# CONTROLSS_PWMXBAR_CONTROLSS_502D1000h register map
Vendor: Texas Instruments
Peripheral module from a debugger description file (folder AM263P).
Registers are 32-bit, read-write, reset 0x0 unless marked. A register's access mark holds for its fields unless they carry their own. Offsets are as the file gives them; lines under a group give offsets from that group; [hi:lo] are bit positions; {n}, {i} and the like mark numbered series; 'fields as' and 'values as' point back to an identical list; <NAME> marks a mode.

## CONTROLSS
0x10 CONTROLSS_PWMXBAR_STATUS ro — Output Signal Status.
  [29:0] PWMXBAR_STATUS_STS — Output Signal Status
0x14 CONTROLSS_PWMXBAR_FLAGINVERT — Output Signal Invert Before Latch.
  [29:0] PWMXBAR_FLAGINVERT_INVERT — Output Signal Invert Before Latch
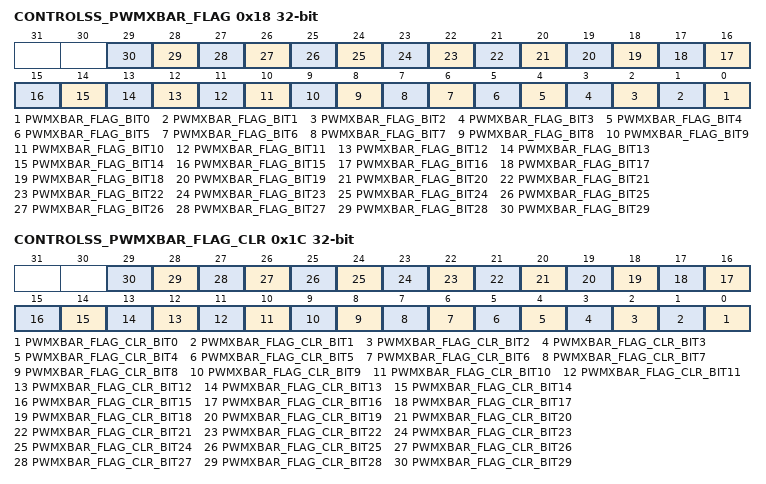
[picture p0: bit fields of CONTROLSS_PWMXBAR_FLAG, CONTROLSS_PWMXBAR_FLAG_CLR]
0x18 CONTROLSS_PWMXBAR_FLAG — Output Signal Latched Flag.
  [n] PWMXBAR_FLAG_BIT{n} (n=0..29) — Output Signal Latched Flag
0x1C CONTROLSS_PWMXBAR_FLAG_CLR — Output Signal Latched Flag Clear.
  [n] PWMXBAR_FLAG_CLR_BIT{n} (n=0..29) — Output Signal Latched Flag Clear
{0x100+0x40*i} CONTROLSS_PWMXBAR{i}_G0 (i=0..29) — PWM XBAR {i} Input Select.
  [19:0] PWMXBAR{i}_G0_SEL — PWM XBAR{i} G0 Input SelectBit0:CMP12SS0.CTRIPLBit1:CMP12SS0.CTRIPHBit2:CMP12SS1.CTRIPLBit3:CMP12SS1.CTRIPHBit4:CMP12SS2.CTRIPLBit5:CMP12SS2.CTRIPHBit6:CMP12SS3.CTRIPLBit7:CMP12SS3.CTRIPHBit8:CMP12SS4.CTRIPLBit9:CMP12SS4.CTRIPHBit10:CMP12SS5.CTRIPLBit11:CMP12SS5.CTRIPHBit12:CMP12SS6.CTRIPLBit13:CMP12SS6.CTRIPHBit14:CMP12SS7.CTRIPLBit15:CMP12SS7.CTRIPHBit16:CMP12SS8.CTRIPLBit17:CMP12SS8.CTRIPHBit18:CMP12SS9.CTRIPLBit19:CMP12SS9.CTRIPH
{0x104+0x40*i} CONTROLSS_PWMXBAR{i}_G1 (i=0..29) — PWM XBAR {i} Input Select.
  [19:0] PWMXBAR{i}_G1_SEL — PWM XBAR{i} G1 Input SelectBit0:CMP8SS0.CTRIPLBit1:CMP8SS0.CTRIPHBit2:CMP8SS1.CTRIPLBit3:CMP8SS1.CTRIPHBit4:CMP8SS2.CTRIPLBit5:CMP8SS2.CTRIPHBit6:CMP8SS3.CTRIPLBit7:CMP8SS3.CTRIPHBit8:CMP8SS4.CTRIPLBit9:CMP8SS4.CTRIPHBit10:CMP8SS5.CTRIPLBit11:CMP8SS5.CTRIPHBit12:CMP8SS6.CTRIPLBit13:CMP8SS6.CTRIPHBit14:CMP8SS7.CTRIPLBit15:CMP8SS7.CTRIPHBit16:CMP8SS8.CTRIPLBit17:CMP8SS8.CTRIPHBit18:CMP8SS9.CTRIPLBit19:CMP8SS9.CTRIPH
{0x108+0x40*i} CONTROLSS_PWMXBAR{i}_G2 (i=0..29) — PWM XBAR {i} Input Select.
  [23:0] PWMXBAR{i}_G2_SEL — PWM XBAR{i} G2 Input SelectBit0:SDFM0.FILT1CEVT1Bit1:SDFM0.FILT1CEVT2Bit2:SDFM0.FILT1COMPHZBit3:SDFM0.FILT2CEVT1Bit4:SDFM0.FILT2CEVT2Bit5:SDFM0.FILT2COMPHZBit6:SDFM0.FILT3CEVT1Bit7:SDFM0.FILT3CEVT2Bit8:SDFM0.FILT3COMPHZBit9:SDFM0.FILT4CEVT1Bit10:SDFM0.FILT4CEVT2Bit11:SDFM0.FILT4COMPHZBit12:SDFM1.FILT1CEVT1Bit13:SDFM1.FILT1CEVT2Bit14:SDFM1.FILT1COMPHZBit15:SDFM1.FILT2CEVT1Bit16:SDFM1.FILT2CEVT2Bit17:SDFM1.FILT2COMPHZBit18:SDFM1.FILT3CEVT1Bit19:SDFM1.FILT3CEVT2Bit20:SDFM1.FILT3COMPHZBit21:SDFM1.FILT4CEVT1Bit22:SDFM1.FILT4CEVT2Bit23:SDFM1.FILT4COMPHZ
{0x10C+0x40*i} CONTROLSS_PWMXBAR{i}_G3 (i=0..28) — PWM XBAR {i} Input Select.
  [31:0] PWMXBAR{i}_G3_SEL — PWM XBAR{i} G3 Input SelectBit1:ADC0.EVT2Bit2:ADC0.EVT3Bit3:ADC0.EVT4Bit4:ADC1.EVT1Bit5:ADC1.EVT2Bit6:ADC1.EVT3Bit7:ADC1.EVT4Bit8:ADC2.EVT1Bit9:ADC2.EVT2Bit10:ADC2.EVT3Bit11:ADC2.EVT4Bit12:ADC3.EVT1Bit13:ADC3.EVT2Bit14:ADC3.EVT3Bit15:ADC3.EVT4Bit16:ADC4.EVT1Bit17:ADC4.EVT2Bit18:ADC4.EVT3Bit19:ADC4.EVT4 Bit20:ADCR0.EVT1Bit21:ADCR0.EVT2Bit22:ADCR0.EVT3Bit23:ADCR0.EVT4Bit24:ADCR1.EVT1Bit25:ADCR1.EVT2Bit26:ADCR1.EVT3Bit27:ADCR1.EVT4 Bit [31:28]: ADC_ASC_CHECKEVENT[3:0]
{0x110+0x40*i} CONTROLSS_PWMXBAR{i}_G4 (i=0..29) — PWM XBAR {i} Input Select.
  [31:0] PWMXBAR{i}_G4_SEL — PWM XBAR{i} G4 input bit select. Input source is INPUT XBAR.1:INPUT XBAR output bit[x] selected0:INPUT XBAR output bit[x] is de-selected
{0x114+0x40*i} CONTROLSS_PWMXBAR{i}_G5 (i=0..29) — PWM XBAR {i} Input Select.
  [31:0] PWMXBAR{i}_G5_SEL — PWM XBAR{i} G5 input bit select. Input source is PWM TRIPOUT.1:PWM TRIPOUT bit[x] selected0:PWM TRIPOUT bit[x] is de-selected
{0x118+0x40*i} CONTROLSS_PWMXBAR{i}_G6 (i=0..29) — PWM XBAR {i} Input Select.
  [31:0] PWMXBAR{i}_G6_SEL — PWM XBAR{i} G6 input bit select. Input source is PWM DEL TRIP1:PWM DEL TRIP bit[x] selected0:PWM DEL TRIP bit[x] is de-selected
{0x11C+0x40*i} CONTROLSS_PWMXBAR{i}_G7 (i=0..29) — PWM XBAR {i} Input Select.
  [31:0] PWMXBAR{i}_G7_SEL — PWM XBAR{i} G7 input bit select. Input source is PWM DEL ACTIVE1:PWM DEL ACTIVE bit[x] selected0:PWM DEL ACTIVE bit[x] is de-selected
0x120 CONTROLSS_PWMXBAR0_G8 — PWM XBAR 0 Input Select.
  [31:0] PWMXBAR0_G8_SEL — PWM XBAR0 G8 Input SelectBit0:EQEP0.ERRBit1:EQEP1.ERRBit2:EQEP2.ERRBit [6:3]: FSIRX0.RX_TRIG4Bit [10:7]: FSIRX1.RX_TRIG4Bit [14:11]: FSIRX2.RX_TRIG4Bit [18:15]: FSIRX3.RX_TRIG4Bit [31:19]: ECAP[12:0].TRIPOUT
{0x124+0x40*i} CONTROLSS_PWMXBAR{i}_G9 (i=0..29) — PWM XBAR {i} Input Select.
  [6:0] PWMXBAR{i}_G9_SEL — PWM XBAR{i} G9 Input Select20:ECAP[15:13].TRIPOUT3:SYNCOUTXBAR04:SYNCOUTXBAR15:SOC_A_SEL6:SOC_B_SEL
0x160 CONTROLSS_PWMXBAR1_G8 — PWM XBAR 1 Input Select.
  [31:0] PWMXBAR1_G8_SEL — PWM XBAR1 G8 Input Select0:EQEP0.ERR1:EQEP1.ERR2:EQEP2.ERR63:FSIRX0.RX_TRIG4107:FSIRX1.RX_TRIG41411:FSIRX2.RX_TRIG41815:FSIRX3.RX_TRIG4 3119:ECAP[12:0].TRIPOUT
{0x120+0x40*i} CONTROLSS_PWMXBAR{i}_G8 (i=2..29) — PWM XBAR {i} Input Select.
  [31:0] PWMXBAR{i}_G8_SEL — PWM XBAR{i} G8 Input SelectBit0:EQEP0.ERRBit1:EQEP1.ERRBit2:EQEP2.ERRBit [6:3]: FSIRX0.RX_TRIG4Bit [10:7]: FSIRX1.RX_TRIG4Bit [14:11]: FSIRX2.RX_TRIG4Bit [18:15]: FSIRX3.RX_TRIG4 Bit [31:19]: ECAP[12:0].TRIPOUT
0x84C CONTROLSS_PWMXBAR29_G3 — PWM XBAR 29 Input Select.
  [31:0] PWMXBAR29_G3_SEL — PWM XBAR29 G3 Input Select1:ADC0.EVT22:ADC0.EVT33:ADC0.EVT44:ADC1.EVT15:ADC1.EVT26:ADC1.EVT37:ADC1.EVT48:ADC2.EVT19:ADC2.EVT210:ADC2.EVT311:ADC2.EVT412:ADC3.EVT113:ADC3.EVT214:ADC3.EVT315:ADC3.EVT416:ADC4.EVT117:ADC4.EVT218:ADC4.EVT319:ADC4.EVT4 20:ADCR0.EVT121:ADCR0.EVT222:ADCR0.EVT323:ADCR0.EVT4 24:ADCR1.EVT125:ADCR1.EVT226:ADCR1.EVT327:ADCR1.EVT42831:ADC_ASC_CHECKEVENT[3:0]
